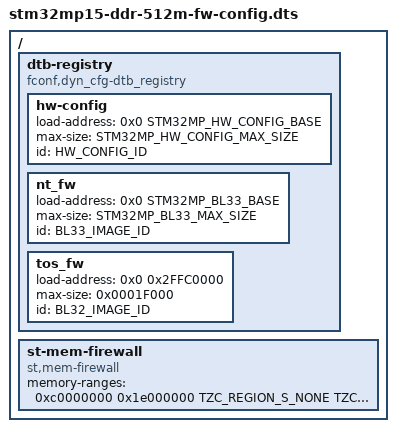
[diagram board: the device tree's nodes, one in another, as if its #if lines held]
// SPDX-License-Identifier: (GPL-2.0+ OR BSD-3-Clause)
/*
 * Copyright (c) 2020, STMicroelectronics - All Rights Reserved
 */

#include <platform_def.h>

#include <common/tbbr/tbbr_img_def.h>
#include <dt-bindings/soc/stm32mp1-tzc400.h>

/dts-v1/;

/ {
	dtb-registry {
		compatible = "fconf,dyn_cfg-dtb_registry";

		hw-config {
			load-address = <0x0 STM32MP_HW_CONFIG_BASE>;
			max-size = <STM32MP_HW_CONFIG_MAX_SIZE>;
			id = <HW_CONFIG_ID>;
		};

		nt_fw {
			load-address = <0x0 STM32MP_BL33_BASE>;
			max-size = <STM32MP_BL33_MAX_SIZE>;
			id = <BL33_IMAGE_ID>;
		};

#ifdef AARCH32_SP_OPTEE
		tos_fw {
			load-address = <0x0 0x2FFC0000>;
			max-size = <0x0001F000>;
			id = <BL32_IMAGE_ID>;
		};
#else
		tos_fw {
			load-address = <0x0 STM32MP_BL32_BASE>;
			max-size = <STM32MP_BL32_SIZE>;
			id = <BL32_IMAGE_ID>;
		};

		tos_fw-config {
			load-address = <0x0 STM32MP_BL32_DTB_BASE>;
			max-size = <STM32MP_BL32_DTB_SIZE>;
			id = <TOS_FW_CONFIG_ID>;
		};
#endif
	};

	st-mem-firewall {
		compatible = "st,mem-firewall";
#ifdef AARCH32_SP_OPTEE
		memory-ranges = <
			0xc0000000 0x1e000000 TZC_REGION_S_NONE TZC_REGION_NSEC_ALL_ACCESS_RDWR
			0xde000000 0x01e00000 TZC_REGION_S_RDWR 0
			0xdfe00000 0x00200000 TZC_REGION_S_NONE
			TZC_REGION_ACCESS_RDWR(STM32MP1_TZC_A7_ID)>;
#else
		memory-ranges = <
			0xc0000000 0x20000000 TZC_REGION_S_NONE TZC_REGION_NSEC_ALL_ACCESS_RDWR>;
#endif
	};
};
